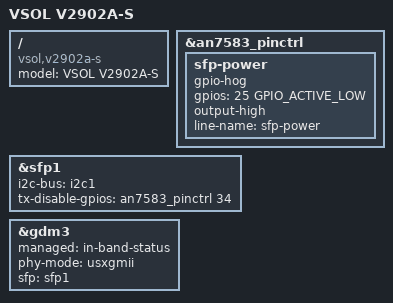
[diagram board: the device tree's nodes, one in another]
// SPDX-License-Identifier: (GPL-2.0-only OR BSD-2-Clause)

#include "an7583-vsol-common.dtsi"

/ {
	model = "VSOL V2902A-S";
	compatible = "vsol,v2902a-s", "airoha,an7583", "airoha,en7583";
};

&an7583_pinctrl {
	sfp-power {
		gpio-hog;
		gpios = <25 GPIO_ACTIVE_LOW>;
		output-high;
		line-name = "sfp-power";
	};
};

&sfp1 {
	i2c-bus = <&i2c1>;
	tx-disable-gpios = <&an7583_pinctrl 34 GPIO_ACTIVE_HIGH>;
};

&gdm3 {
	managed = "in-band-status";
	phy-mode = "usxgmii";
	sfp = <&sfp1>;
};
